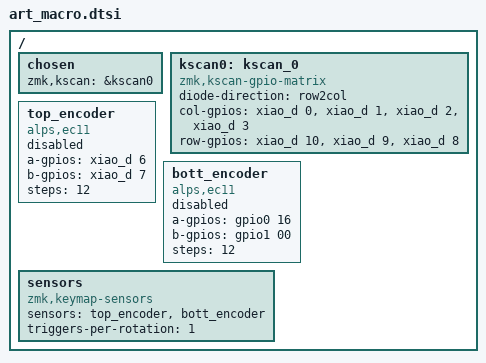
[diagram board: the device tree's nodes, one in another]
/ {
    chosen {
        zmk,kscan = &kscan0;
    };

    kscan0: kscan_0 {
        compatible = "zmk,kscan-gpio-matrix";
        diode-direction = "row2col";

        col-gpios
            = <&xiao_d 0 (GPIO_ACTIVE_HIGH | GPIO_PULL_DOWN)>
            , <&xiao_d 1 (GPIO_ACTIVE_HIGH | GPIO_PULL_DOWN)>
            , <&xiao_d 2 (GPIO_ACTIVE_HIGH | GPIO_PULL_DOWN)>
            , <&xiao_d 3 (GPIO_ACTIVE_HIGH | GPIO_PULL_DOWN)>
            ;

        row-gpios
            = <&xiao_d 10 GPIO_ACTIVE_HIGH>
            , <&xiao_d 9 GPIO_ACTIVE_HIGH>
            , <&xiao_d 8 GPIO_ACTIVE_HIGH>
            ;
    };

    top_encoder:  top_encoder {
        compatible = "alps,ec11";
        a-gpios = <&xiao_d 6 (GPIO_ACTIVE_HIGH | GPIO_PULL_UP)>;
        b-gpios = <&xiao_d 7 (GPIO_ACTIVE_HIGH | GPIO_PULL_UP)>;
        steps = <12>;
        status = "disabled";
    };

    bott_encoder:  bott_encoder {
        compatible = "alps,ec11";
        a-gpios = <&gpio0 16 (GPIO_ACTIVE_HIGH | GPIO_PULL_UP)>;
        b-gpios = <&gpio1 00 (GPIO_ACTIVE_HIGH | GPIO_PULL_UP)>;
        steps = <12>;
        status = "disabled";
    };

    sensors: sensors {
        compatible = "zmk,keymap-sensors";
        sensors = <&top_encoder &bott_encoder>;
        triggers-per-rotation = <1>;
    };
};
